AUTOSAR XML (schema 4.0)
standard types defined: float32, float64, sint16, sint32, sint8, uint16, uint32, uint8, void, boolean
package /MappingSets
  data type mapping set MappingSet: mode-request-type-map{implementation-data-type=uint8, mode-group=SeatMode}
package /PortInterfaces/ModeSwitch
  mode switch interface MsIf_SeatMode
    mode group SeatMode: type=SeatMode
  mode declaration group SeatMode: category=ALPHABETIC_ORDER, initial-mode=INIT, on-transition-value=255
    mode AUTO
    mode INIT
    mode MANUAL
package /SoftwareComponents
  swc implementation Impl_SeatHandle: programming-language=C, sw-version=1.0.0, vendor-id=255, behavior=Ibhv_SeatHandle
    code-descriptors:
      code Code: artifact-descriptors=autosar-engineering-object={short-label=SWC.c, category=SWSRC}
    resource consumption ResourceConsumption
  swc implementation Impl_SeatMgr: programming-language=C, sw-version=1.0.0, vendor-id=255, behavior=Ibhv_SeatMgr
    code-descriptors:
      code Code: artifact-descriptors=autosar-engineering-object={short-label=SWC.c, category=SWSRC}
    resource consumption ResourceConsumption
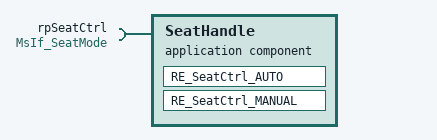
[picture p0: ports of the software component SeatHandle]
  application sw component type SeatHandle
    require port rpSeatCtrl: required-interface=MsIf_SeatMode
    behavior Ibhv_SeatHandle: data-type-mapping=MappingSet, handle-termination-and-restart=NO-SUPPORT
      swc mode switch event MSE_rpSeatCtrl_AUTO_ON_ENTRY: start-on-event=RE_SeatCtrl_AUTO, activation=ON-ENTRY, mode=rpSeatCtrl.SeatMode.AUTO
      swc mode switch event MSE_rpSeatCtrl_MANUAL_ON_ENTRY: start-on-event=RE_SeatCtrl_MANUAL, activation=ON-ENTRY, mode=rpSeatCtrl.SeatMode.MANUAL
      runnable RE_SeatCtrl_AUTO
      runnable RE_SeatCtrl_MANUAL
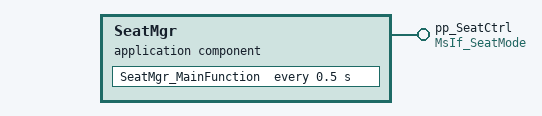
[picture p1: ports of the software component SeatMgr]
  application sw component type SeatMgr
    provide port pp_SeatCtrl: provided-interface=MsIf_SeatMode
    behavior Ibhv_SeatMgr: data-type-mapping=MappingSet, handle-termination-and-restart=NO-SUPPORT
      timing event TE_SeatMgr_MainFunction_500ms: start-on-event=SeatMgr_MainFunction, period=0.5
      runnable SeatMgr_MainFunction
        mode switch point MSP_pp_SeatCtrl_pp_SeatCtrl: mode-group=pp_SeatCtrl.SeatMode
package /Compositions
  composition sw component type SeatHandle_MSComposition
    component SeatHandle: type=SeatHandle
    component SeatMgr: type=SeatMgr
    connect SeatMgr.pp_SeatCtrl -> SeatHandle.rpSeatCtrl
